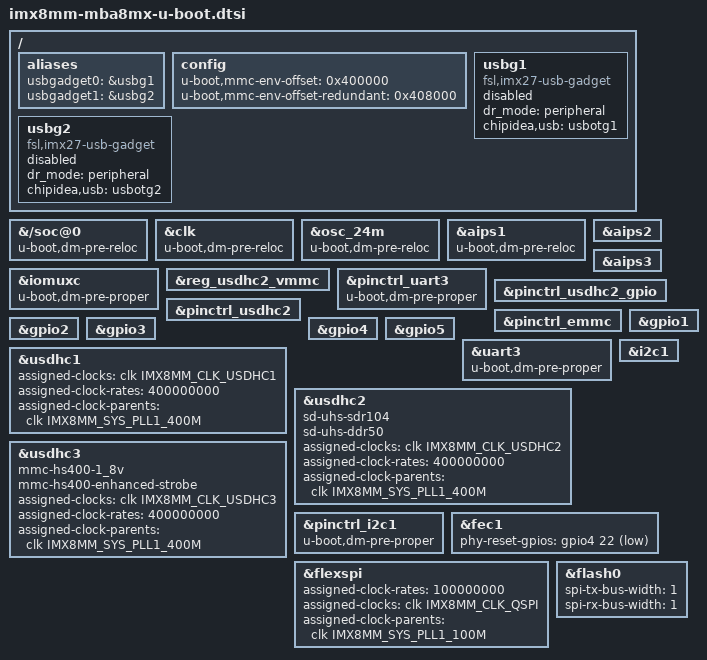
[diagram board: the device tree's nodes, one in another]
// SPDX-License-Identifier: GPL-2.0-or-later OR MIT
/*
 * Copyright 2020 - 2021 TQ-Systems GmbH
 */

/ {
	aliases {
		usbgadget0 = &usbg1;
		usbgadget1 = &usbg2;
	};

	config {
		/* 32 kiB redundant env */
		u-boot,mmc-env-offset = <0x400000>;
		u-boot,mmc-env-offset-redundant = <0x408000>;
	};

	usbg1: usbg1 {
		compatible = "fsl,imx27-usb-gadget";
		dr_mode = "peripheral";
		chipidea,usb = <&usbotg1>;
		status = "disabled";
	};

	usbg2: usbg2 {
		compatible = "fsl,imx27-usb-gadget";
		dr_mode = "peripheral";
		chipidea,usb = <&usbotg2>;
		status = "disabled";
	};
};

&{/soc@0} {
	u-boot,dm-pre-reloc;
	u-boot,dm-spl;
};

&clk {
	u-boot,dm-spl;
	u-boot,dm-pre-reloc;
	/delete-property/ assigned-clocks;
	/delete-property/ assigned-clock-parents;
	/delete-property/ assigned-clock-rates;
};

&osc_24m {
	u-boot,dm-spl;
	u-boot,dm-pre-reloc;
};

&aips1 {
	u-boot,dm-spl;
	u-boot,dm-pre-reloc;
};

&aips2 {
	u-boot,dm-spl;
};

&aips3 {
	u-boot,dm-spl;
};

&iomuxc {
	u-boot,dm-spl;
	u-boot,dm-pre-proper;
};

&reg_usdhc2_vmmc {
	u-boot,dm-spl;
};

&pinctrl_uart3 {
	u-boot,dm-spl;
	u-boot,dm-pre-proper;
};

&pinctrl_usdhc2_gpio {
	u-boot,dm-spl;
};

&pinctrl_usdhc2 {
	u-boot,dm-spl;
};

&pinctrl_emmc {
	u-boot,dm-spl;
};

&gpio1 {
	u-boot,dm-spl;
};

&gpio2 {
	u-boot,dm-spl;
};

&gpio3 {
	u-boot,dm-spl;
};

&gpio4 {
	u-boot,dm-spl;
};

&gpio5 {
	u-boot,dm-spl;
};

&uart3 {
	u-boot,dm-spl;
	u-boot,dm-pre-proper;
};

&usdhc1 {
	u-boot,dm-spl;
	assigned-clocks = <&clk IMX8MM_CLK_USDHC1>;
	assigned-clock-rates = <400000000>;
	assigned-clock-parents = <&clk IMX8MM_SYS_PLL1_400M>;
};

&usdhc2 {
	u-boot,dm-spl;
	sd-uhs-sdr104;
	sd-uhs-ddr50;
	assigned-clocks = <&clk IMX8MM_CLK_USDHC2>;
	assigned-clock-rates = <400000000>;
	assigned-clock-parents = <&clk IMX8MM_SYS_PLL1_400M>;
};

&usdhc3 {
	u-boot,dm-spl;
	mmc-hs400-1_8v;
	mmc-hs400-enhanced-strobe;
	/*
	 * prevents voltage switch warn: driver will switch even at
	 * fixed voltage
	 */
	/delete-property/ vmmc-supply;
	/delete-property/ vqmmc-supply;
	assigned-clocks = <&clk IMX8MM_CLK_USDHC3>;
	assigned-clock-rates = <400000000>;
	assigned-clock-parents = <&clk IMX8MM_SYS_PLL1_400M>;
};

&i2c1 {
	u-boot,dm-spl;
};

&pinctrl_i2c1 {
	u-boot,dm-spl;
	u-boot,dm-pre-proper;
};

&fec1 {
	phy-reset-gpios = <&gpio4 22 GPIO_ACTIVE_LOW>;
};

&flexspi {
	assigned-clock-rates = <100000000>;
	assigned-clocks = <&clk IMX8MM_CLK_QSPI>;
	assigned-clock-parents = <&clk IMX8MM_SYS_PLL1_100M>;
};

&flash0 {
	spi-tx-bus-width = <1>;
	spi-rx-bus-width = <1>;
};
